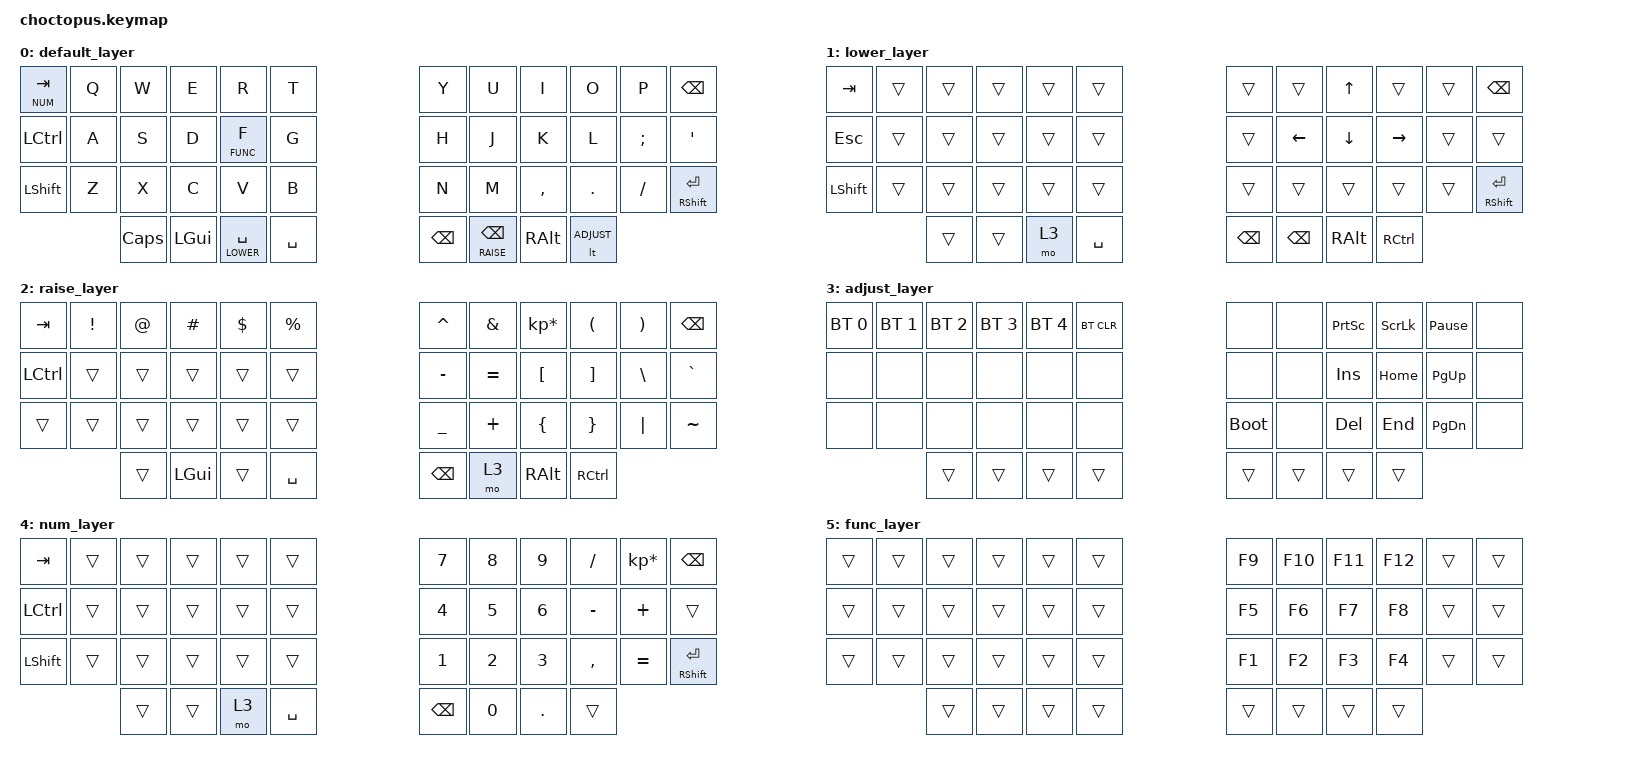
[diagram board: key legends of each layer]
/*
 * Copyright (c) 2021 The ZMK Contributors
 *
 * SPDX-License-Identifier: MIT
 */

#define DEFAULT 0
#define LOWER   1
#define RAISE   2
#define ADJUST  3
#define NUM     4
#define FUNC    5

#include <behaviors.dtsi>
#include <dt-bindings/zmk/keys.h>
#include <dt-bindings/zmk/bt.h>

&mt {
    tapping-term-ms = <400>;
};

/ {
    keymap {
        compatible = "zmk,keymap";


    default_layer {
            bindings = <
                &lt NUM TAB  &kp Q      &kp W     &kp E     &kp R      &kp T                            &kp Y      &kp U      &kp I      &kp O     &kp P      &kp BSPC
        &kp LCTRL           &kp A           &kp S       &kp D     &lt FUNC F        &kp G                &kp H     &kp J     &kp K      &kp L      &kp SEMI     &kp SQT
        &kp LSHFT           &kp Z           &kp X       &kp C     &kp V             &kp B                &kp N     &kp M     &kp COMMA  &kp DOT    &kp FSLH     &mt RSHFT RET
                                            &kp CAPS    &kp LGUI  &lt LOWER SPACE   &kp SPACE            &kp BSPC  &lt RAISE BSPC       &kp RALT   &lt ADJUST
                >;
        };

    lower_layer {
            bindings = <
        &kp TAB     &trans   &trans  &trans   &trans  &trans                        &trans    &trans    &kp UP      &trans     &trans  &kp BSPC
        &kp ESC     &trans   &trans  &trans   &trans  &trans                        &trans    &kp LEFT  &kp DOWN    &kp RIGHT  &trans  &trans
        &kp LSHFT   &trans   &trans  &trans   &trans  &trans                        &trans    &trans    &trans      &trans     &trans  &mt RSHFT RET
                             &trans  &trans   &mo 3   &kp SPACE                     &kp BSPC  &kp BSPC  &kp RALT    &kp RCTRL
                >;
        };

    raise_layer {
            bindings = <
        &kp TAB   &kp EXCL  &kp AT  &kp HASH &kp DLLR &kp PRCNT                       &kp CARET           &kp AMPS          &kp KP_MULTIPLY     &kp LPAR     &kp RPAR   &kp BSPC
        &kp LCTRL &trans    &trans  &trans   &trans   &trans                          &kp MINUS           &kp EQUAL         &kp LBKT            &kp RBKT     &kp BSLH   &kp GRAVE
        &trans    &trans    &trans  &trans   &trans   &trans                          &kp UNDER           &kp PLUS          &kp LBRC            &kp RBRC     &kp PIPE   &kp TILDE
                            &trans  &kp LGUI &trans   &kp SPACE                       &kp BSPC            &mo 3             &kp RALT            &kp RCTRL
                >;
        };

    adjust_layer {
            bindings = <
        &bt BT_SEL 0  &bt BT_SEL 1    &bt BT_SEL 2    &bt BT_SEL 3    &bt BT_SEL 4    &bt BT_CLR                &none         &none         &kp PSCRN     &kp SLCK    &kp PAUSE_BREAK   &none
        &none         &none           &none           &none           &none           &none                     &none         &none         &kp INSERT    &kp HOME    &kp PG_UP         &none
        &none         &none           &none           &none           &none           &none                     &bootloader   &none         &kp DEL       &kp END     &kp PG_DN         &none
                                      &trans          &trans          &trans          &trans                    &trans        &trans        &trans        &trans
                >;
        };

    num_layer {
            bindings = <
        &kp TAB     &trans   &trans  &trans   &trans  &trans                        &kp N7   &kp N8    &kp N9    &kp FSLH    &kp KP_MULTIPLY   &kp BSPC
        &kp LCTRL   &trans   &trans  &trans   &trans  &trans                        &kp N4   &kp N5    &kp N6    &kp MINUS   &kp PLUS          &trans
        &kp LSHFT   &trans   &trans  &trans   &trans  &trans                        &kp N1   &kp N2    &kp N3    &kp COMMA   &kp EQUAL         &mt RSHFT RET
                             &trans  &trans   &mo 3   &kp SPACE                     &kp BSPC &kp N0    &kp DOT   &trans
            >;
        };

     func_layer {
            bindings = <
        &trans      &trans    &trans   &trans    &trans   &trans                     &kp F9    &kp F10   &kp F11   &kp F12  &trans  &trans
        &trans      &trans    &trans   &trans    &trans   &trans                     &kp F5    &kp F6    &kp F7    &kp F8   &trans  &trans
        &trans      &trans    &trans   &trans    &trans   &trans                     &kp F1    &kp F2    &kp F3    &kp F4   &trans  &trans
                              &trans   &trans    &trans   &trans                     &trans    &trans    &trans    &trans
            >;
        };

    };
};
